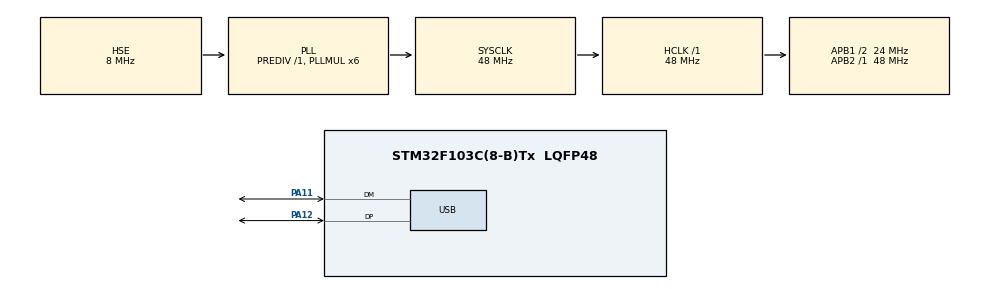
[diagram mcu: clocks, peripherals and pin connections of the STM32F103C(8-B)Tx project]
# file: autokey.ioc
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Mcu.Family=STM32F1
Mcu.Name=STM32F103C(8-B)Tx
Mcu.Package=LQFP48
NVIC.PriorityGroup=NVIC_PRIORITYGROUP_4
NVIC.USB_LP_CAN1_RX0_IRQn=true\:0\:0\:false\:false\:true\:false\:true\:true
PA11.Mode=Device
PA11.Signal=USB_DM
PA12.Mode=Device
PA12.Signal=USB_DP
PA13.Mode=Serial_Wire
PA13.Signal=SYS_JTMS-SWDIO
PA14.Mode=Serial_Wire
PA14.Signal=SYS_JTCK-SWCLK
PD0-OSC_IN.Mode=HSE-External-Oscillator
PD0-OSC_IN.Signal=RCC_OSC_IN
PD1-OSC_OUT.Mode=HSE-External-Oscillator
PD1-OSC_OUT.Signal=RCC_OSC_OUT
ProjectManager.HeapSize=0x200
ProjectManager.StackSize=0x400
ProjectManager.TargetToolchain=MDK-ARM V5
RCC.AHBFreq_Value=48000000
RCC.APB1CLKDivider=RCC_HCLK_DIV2
RCC.APB1Freq_Value=24000000
RCC.APB1TimFreq_Value=48000000
RCC.APB2Freq_Value=48000000
RCC.APB2TimFreq_Value=48000000
RCC.HCLKFreq_Value=48000000
RCC.PLLMUL=RCC_PLL_MUL6
RCC.SYSCLKFreq_VALUE=48000000
RCC.SYSCLKSource=RCC_SYSCLKSOURCE_PLLCLK
RCC.USBFreq_Value=48000000
USB_DEVICE.CLASS_NAME_FS=HID
USB_DEVICE.VirtualMode=Hid
USB_DEVICE.VirtualModeFS=Hid_FS
VP_USB_DEVICE_VS_USB_DEVICE_HID_FS.Mode=HID_FS
board=custom

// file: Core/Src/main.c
/* USER CODE BEGIN Header */
/**
  ******************************************************************************
  * @file           : main.c
  * @brief          : Main program body
  ******************************************************************************
  * @attention
  *
  * Copyright (c) 2023 STMicroelectronics.
  * All rights reserved.
  *
  * This software is licensed under terms that can be found in the LICENSE file
  * in the root directory of this software component.
  * If no LICENSE file comes with this software, it is provided AS-IS.
  *
  ******************************************************************************
  */
/* USER CODE END Header */
#include "main.h"
#include "usb_device.h"
#include "usbd_hid.h"

/* USER CODE BEGIN Includes */
uint8_t report[8] = {
	0, //MODIFIER
	0, //RESERVED
	0, //KEYCODE1
	0, //KEYCODE2
	0, //KEYCODE3
	0, //KEYCODE4
	0, //KEYCODE5
	0  //KEYCODE6
};
extern USBD_HandleTypeDef hUsbDeviceFS;
/* USER CODE END Includes */

void SystemClock_Config(void);
static void MX_GPIO_Init(void);

int main(void)
{

  /* MCU Configuration--------------------------------------------------------*/

  /* Reset of all peripherals, Initializes the Flash interface and the Systick. */
  HAL_Init();

  /* Configure the system clock */
  SystemClock_Config();

  /* Initialize all configured peripherals */
  MX_GPIO_Init();
  MX_USB_DEVICE_Init();

  /* Infinite loop */
  /* USER CODE BEGIN WHILE */
  while (1)
  {
		uint8_t Key =rand()%30+1;
		if(Key!=4)
		{
			report[2] = Key;
			USBD_HID_SendReport(&hUsbDeviceFS, report, sizeof (report));
			HAL_Delay(50);

			report[2] = 0;
			USBD_HID_SendReport(&hUsbDeviceFS, report, sizeof (report));
			HAL_Delay(50);
		}
		else {
			report[2] = Key;
			report[0] = 1;
			USBD_HID_SendReport(&hUsbDeviceFS, report, sizeof (report));
			HAL_Delay(50);

			report[2] = 76;
			report[0] = 0;
			USBD_HID_SendReport(&hUsbDeviceFS, report, sizeof (report));
			HAL_Delay(50);

			report[2] = 0;
			USBD_HID_SendReport(&hUsbDeviceFS, report, sizeof (report));
			HAL_Delay(50);

		}

  }
  /* USER CODE END 3 */
}

void SystemClock_Config(void)
{
  RCC_OscInitTypeDef RCC_OscInitStruct = {0};
  RCC_ClkInitTypeDef RCC_ClkInitStruct = {0};
  RCC_PeriphCLKInitTypeDef PeriphClkInit = {0};

  /** Initializes the RCC Oscillators according to the specified parameters
  * in the RCC_OscInitTypeDef structure.
  */
  RCC_OscInitStruct.OscillatorType = RCC_OSCILLATORTYPE_HSE;
  RCC_OscInitStruct.HSEState = RCC_HSE_ON;
  RCC_OscInitStruct.HSEPredivValue = RCC_HSE_PREDIV_DIV1;
  RCC_OscInitStruct.HSIState = RCC_HSI_ON;
  RCC_OscInitStruct.PLL.PLLState = RCC_PLL_ON;
  RCC_OscInitStruct.PLL.PLLSource = RCC_PLLSOURCE_HSE;
  RCC_OscInitStruct.PLL.PLLMUL = RCC_PLL_MUL6;
  if (HAL_RCC_OscConfig(&RCC_OscInitStruct) != HAL_OK)
  {
    Error_Handler();
  }

  /** Initializes the CPU, AHB and APB buses clocks
  */
  RCC_ClkInitStruct.ClockType = RCC_CLOCKTYPE_HCLK|RCC_CLOCKTYPE_SYSCLK
                              |RCC_CLOCKTYPE_PCLK1|RCC_CLOCKTYPE_PCLK2;
  RCC_ClkInitStruct.SYSCLKSource = RCC_SYSCLKSOURCE_PLLCLK;
  RCC_ClkInitStruct.AHBCLKDivider = RCC_SYSCLK_DIV1;
  RCC_ClkInitStruct.APB1CLKDivider = RCC_HCLK_DIV2;
  RCC_ClkInitStruct.APB2CLKDivider = RCC_HCLK_DIV1;

  if (HAL_RCC_ClockConfig(&RCC_ClkInitStruct, FLASH_LATENCY_1) != HAL_OK)
  {
    Error_Handler();
  }
  PeriphClkInit.PeriphClockSelection = RCC_PERIPHCLK_USB;
  PeriphClkInit.UsbClockSelection = RCC_USBCLKSOURCE_PLL;
  if (HAL_RCCEx_PeriphCLKConfig(&PeriphClkInit) != HAL_OK)
  {
    Error_Handler();
  }
}

static void MX_GPIO_Init(void)
{

  /* GPIO Ports Clock Enable */
  __HAL_RCC_GPIOD_CLK_ENABLE();
  __HAL_RCC_GPIOA_CLK_ENABLE();

}

void Error_Handler(void)
{
  __disable_irq();
  while (1)
  {
  }
}
